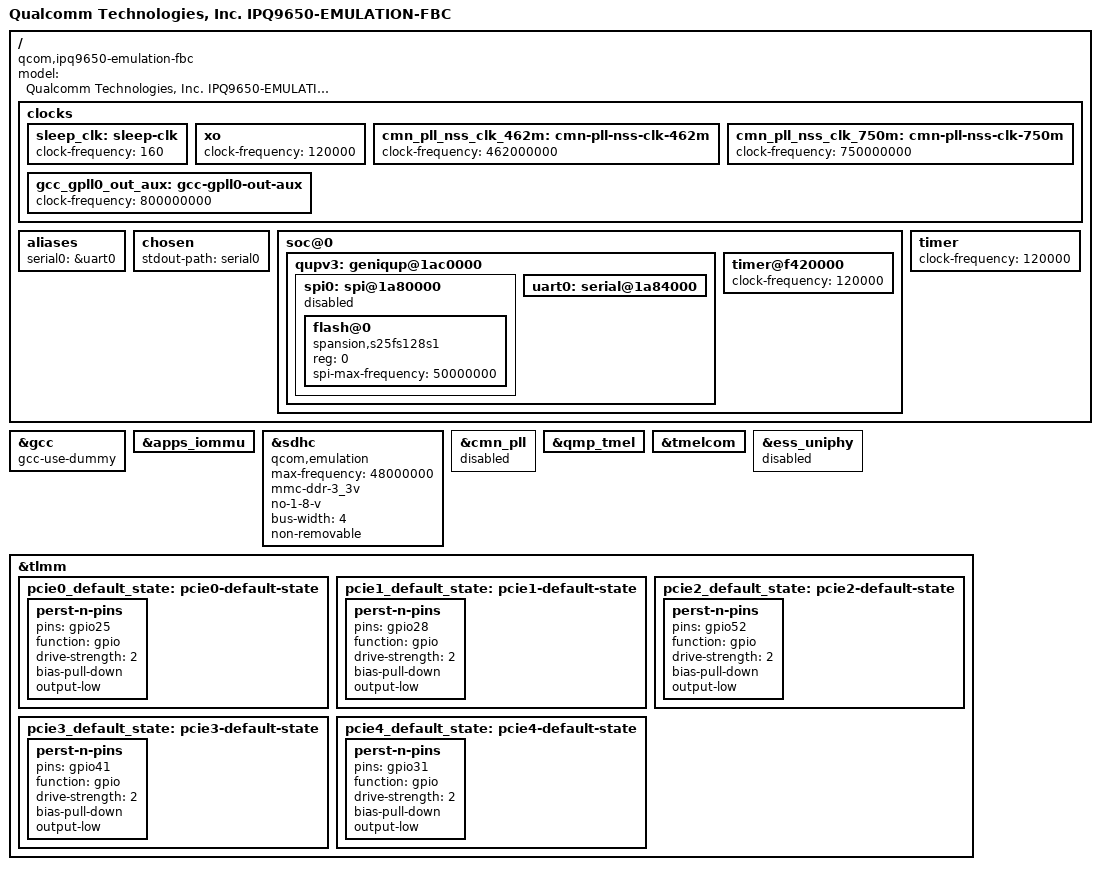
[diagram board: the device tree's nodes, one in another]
// SPDX-License-Identifier: (GPL-2.0+ OR BSD-3-Clause)
/*
 * IPQ9650 Emulation board device tree source
 *
 * Copyright (c) 2020-2021 The Linux Foundation. All rights reserved.
 * Copyright (c) Qualcomm Technologies, Inc. and/or its subsidiaries.
 */

/dts-v1/;

#include "ipq9650.dtsi"

/ {
	model = "Qualcomm Technologies, Inc. IPQ9650-EMULATION-FBC";
	compatible = "qcom,ipq9650-emulation-fbc", "qcom,ipq9650";

	/* Timer freq for rumi = timer freq / 200 */
	clocks {
		/* sleep-clk freq for rumi = sleep-clk freq (32000) / 200 */
		sleep_clk: sleep-clk {
			clock-frequency = <160>;
		};

		/* xo freq for rumi = xo freq (24000000) / 200 */
		xo: xo {
			clock-frequency = <120000>;
		};

		cmn_pll_nss_clk_462m: cmn-pll-nss-clk-462m {
			clock-frequency = <462000000>;
		};

		cmn_pll_nss_clk_750m: cmn-pll-nss-clk-750m {
			clock-frequency = <750000000>;
		};

		gcc_gpll0_out_aux: gcc-gpll0-out-aux {
			clock-frequency = <800000000>;
		};
	};

	aliases {
		serial0 = &uart0;
	};

	chosen {
		stdout-path = "serial0";
	};

	soc@0 {
		qupv3: geniqup@1ac0000 {
			status = "okay";

			spi0: spi@1a80000 {
				status = "disabled";

				flash@0 {
					compatible = "spansion,s25fs128s1", "jedec,spi-nor";
					#address-cells = <1>;
					#size-cells = <1>;
					reg = <0>;
					spi-max-frequency = <50000000>;
				};
			};

			uart0: serial@1a84000 {
				status = "okay";
			};
		};

		/* Timer freq for rumi = timer freq (24000000) / 200 */
		timer@f420000 {
			clock-frequency = <120000>;
		};
	};

	/* Timer freq for rumi = timer freq (24000000) / 200 */
	timer {
		clock-frequency = <120000>;
	};
};

&gcc {
	gcc-use-dummy;
};

&apps_iommu {
	status = "okay";
};

&sdhc {
	qcom,emulation;
	/* override the frequency to 48Mhz for emulation platform */
	max-frequency = <48000000>;
	/* Force 3.3V, because only that will support on emulation platform */
	mmc-ddr-3_3v;
	/* quirk to disable SDR104, SDR50 modes */
	no-1-8-v;
	bus-width = <4>;
	non-removable;
	status = "okay";
};

&cmn_pll {
	status = "disabled";
};

&qmp_tmel {
	status = "okay";
};

&tmelcom {
	status = "okay";
};

&ess_uniphy {
	status = "disabled";
};

&tlmm {
	pcie0_default_state: pcie0-default-state {
		perst-n-pins {
			pins = "gpio25";
			function = "gpio";
			drive-strength = <2>;
			bias-pull-down;
			output-low;
		};
	};

	pcie1_default_state: pcie1-default-state {
		perst-n-pins {
			pins = "gpio28";
			function = "gpio";
			drive-strength = <2>;
			bias-pull-down;
			output-low;
		};
	};

	pcie2_default_state: pcie2-default-state {
		perst-n-pins {
			pins = "gpio52";
			function = "gpio";
			drive-strength = <2>;
			bias-pull-down;
			output-low;
		};
	};

	pcie3_default_state: pcie3-default-state {
		perst-n-pins {
			pins = "gpio41";
			function = "gpio";
			drive-strength = <2>;
			bias-pull-down;
			output-low;
		};
	};

	pcie4_default_state: pcie4-default-state {
		perst-n-pins {
			pins = "gpio31";
			function = "gpio";
			drive-strength = <2>;
			bias-pull-down;
			output-low;
		};
	};
};
